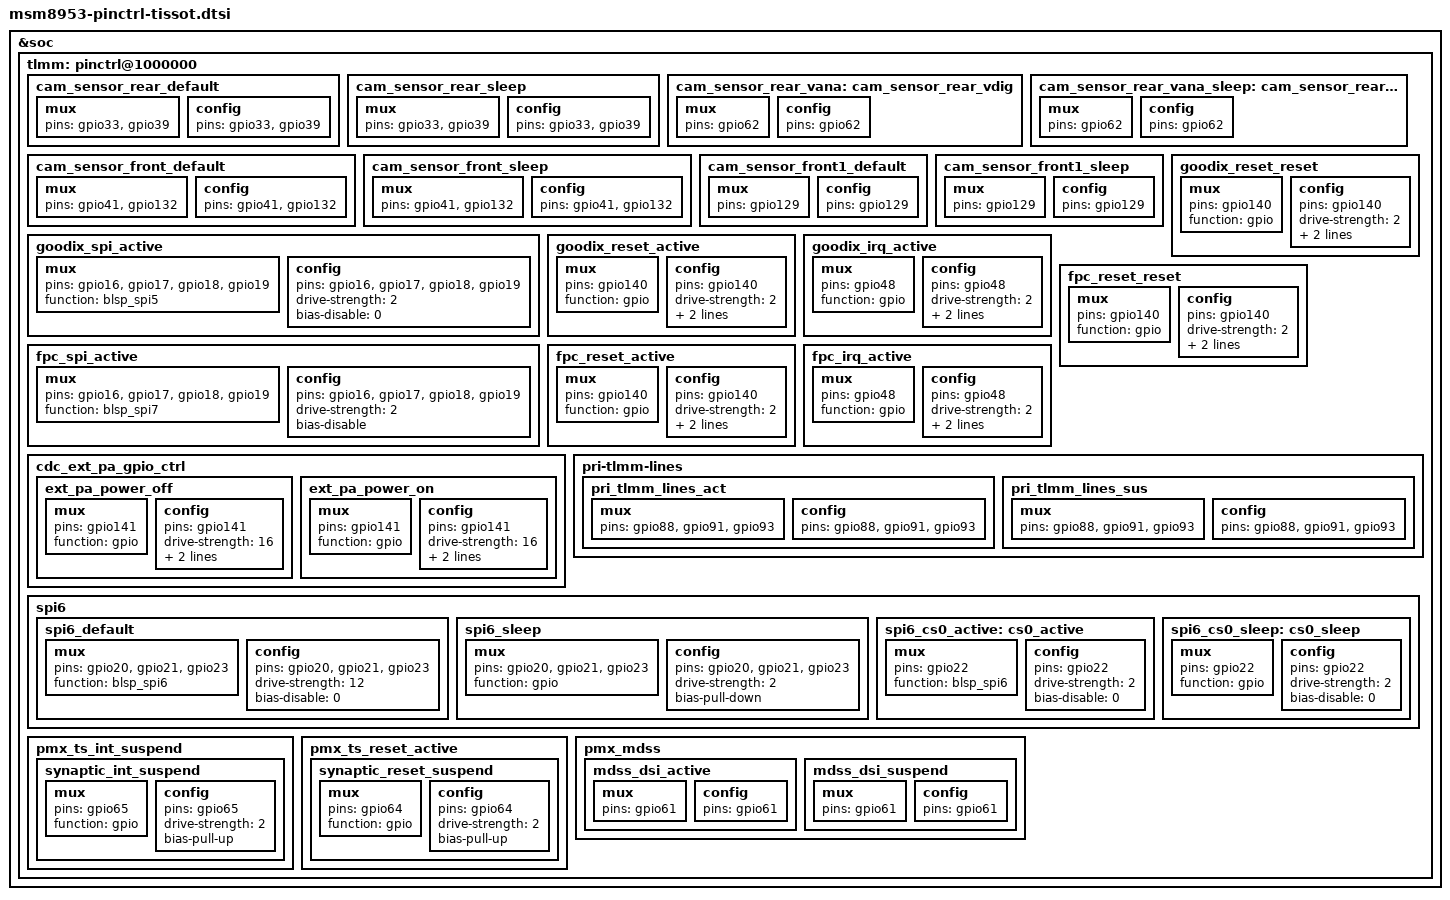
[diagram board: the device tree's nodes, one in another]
/*
 * Copyright (c) 2015-2017, The Linux Foundation. All rights reserved.
 *
 * This program is free software; you can redistribute it and/or modify
 * it under the terms of the GNU General Public License version 2 and
 * only version 2 as published by the Free Software Foundation.
 *
 * This program is distributed in the hope that it will be useful,
 * but WITHOUT ANY WARRANTY; without even the implied warranty of
 * MERCHANTABILITY or FITNESS FOR A PARTICULAR PURPOSE.  See the
 * GNU General Public License for more details.
 */

&soc {
	tlmm: pinctrl@1000000 {
		cam_sensor_rear_default: cam_sensor_rear_default {
			/* RESET, STANDBY */
			mux {
				pins = "gpio33", "gpio39";
			};

			config {
				pins = "gpio33","gpio39";
			};
		};

		cam_sensor_rear_sleep: cam_sensor_rear_sleep {
			/* RESET, STANDBY */
			mux {
				pins = "gpio33","gpio39";
			};

			config {
				pins = "gpio33","gpio39";
			};
		};

		/delete-node/ cam_sensor_ir_cut_default;
		/delete-node/ cam_sensor_ir_cut_sleep;
		/delete-node/ cam_sensor_rear_default1;
		/delete-node/ cam_sensor_rear_sleep1;

		cam_sensor_rear_vana: cam_sensor_rear_vdig {
			/* VDIG */
			mux {
				pins = "gpio62";
			};

			config {
				pins = "gpio62";
			};
		};

		cam_sensor_rear_vana_sleep: cam_sensor_rear_vdig_sleep {
			/* VDIG */
			mux {
				pins = "gpio62";
			};

			config {
				pins = "gpio62";
			};
		};

		/delete-node/ cam_sensor_rear_vdig1;
		/delete-node/ cam_sensor_rear_vdig_sleep1;

		cam_sensor_front_default: cam_sensor_front_default {
			/* RESET, STANDBY */
			mux {
				pins = "gpio41","gpio132";
			};

			config {
				pins = "gpio41","gpio132";
			};
		};

		cam_sensor_front_sleep: cam_sensor_front_sleep {
			/* RESET, STANDBY */
			mux {
				pins = "gpio41","gpio132";
			};

			config {
				pins = "gpio41","gpio132";
			};
		};

		cam_sensor_front1_default: cam_sensor_front1_default {
			/* RESET, STANDBY */
			mux {
				pins = "gpio129";
			};

			config {
				pins = "gpio129";
			};
		};

		cam_sensor_front1_sleep: cam_sensor_front1_sleep {
			/* RESET, STANDBY */
			mux {
				pins = "gpio129";
			};

			config {
				pins = "gpio129";
			};
		};

		goodix_spi_active: goodix_spi_active{
			mux {
				pins = "gpio16", "gpio17", "gpio18", "gpio19";
				function = "blsp_spi5";
			};
			config {
				pins = "gpio16", "gpio17", "gpio18", "gpio19";
				drive-strength = <2>;
				bias-disable = <0>;
			};
		};
		goodix_reset_reset: goodix_reset_reset{
			mux {
				pins = "gpio140";
				function = "gpio";
			};
			config {
				pins = "gpio140";
				drive-strength = <2>;
				bias-disable = <0>;
				output-low;
			};
		};
		goodix_reset_active: goodix_reset_active{
			mux {
				pins = "gpio140";
				function = "gpio";
			};
			config {
				pins = "gpio140";
				drive-strength = <2>;
				bias-disable = <0>;
				output-high;
			};
		};
		goodix_irq_active: goodix_irq_active {
			mux {
				pins = "gpio48";
				function = "gpio";
			};
			config {
				pins = "gpio48";
				drive-strength = <2>;
				bias-disable = <0>;
				input-enable;
			};
		};

		fpc_spi_active: fpc_spi_active {
			mux {
				pins = "gpio16", "gpio17", "gpio18", "gpio19";
				function = "blsp_spi7";
			};

			config {
				pins = "gpio16", "gpio17", "gpio18", "gpio19";
				drive-strength = <2>;
				bias-disable;
			};
		};
		fpc_reset_reset: fpc_reset_reset {
			mux {
				pins = "gpio140";
				function = "gpio";
			};
			config {
				pins = "gpio140";
				drive-strength = <2>;
				bias-disable;
				output-low;
			};
		};
		fpc_reset_active: fpc_reset_active {
			mux {
				pins = "gpio140";
				function = "gpio";
			};
			config {
				pins = "gpio140";
				drive-strength = <2>;
				bias-disable;
				output-high;
			};
		};
		fpc_irq_active: fpc_irq_active {
			mux {
				pins = "gpio48";
				function = "gpio";
			};
			config {
				pins = "gpio48";
				drive-strength = <2>;
				bias-disable;
				input-enable;
			};
		};

		cdc_ext_pa_gpio_ctrl {
			ext_pa_power_off:ext_pa_power_off{
				mux {
					pins = "gpio141";
					function = "gpio";
				};
				config {
					pins = "gpio141";
					drive-strength = <16>;
					bias-disable;
					output-low;
				};
			};
			ext_pa_power_on:ext_pa_power_on{
				mux {
					pins = "gpio141";
					function = "gpio";
				};
				config {
					pins = "gpio141";
					drive-strength = <16>;
					bias-pull-down;
					output-high;
				};
			};
		};

		pri-tlmm-lines {
			pri_tlmm_lines_act: pri_tlmm_lines_act {
				mux {
					pins = "gpio88", "gpio91", "gpio93";
				};

				config {
					pins = "gpio88", "gpio91", "gpio93";
				};
			};

			pri_tlmm_lines_sus: pri_tlmm_lines_sus {
				mux {
					pins = "gpio88", "gpio91", "gpio93";
				};

				config {
					pins = "gpio88", "gpio91", "gpio93";
				};
			};
		};

		spi6 {
			spi6_default: spi6_default {
				/* active state */
				mux {
					/* MOSI, MISO, CLK */
					pins = "gpio20", "gpio21", "gpio23";
					function = "blsp_spi6";
				};

				config {
					pins = "gpio20", "gpio21", "gpio23";
					drive-strength = <12>; /* 12 MA */
					bias-disable = <0>; /* No PULL */
				};
			};

			spi6_sleep: spi6_sleep {
				/* suspended state */
				mux {
					/* MOSI, MISO, CLK */
					pins = "gpio20", "gpio21", "gpio23";
					function = "gpio";
				};

				config {
					pins = "gpio20", "gpio21", "gpio23";
					drive-strength = <2>; /* 2 MA */
					bias-pull-down; /* PULL Down */
				};
			};

			spi6_cs0_active: cs0_active {
				/* CS */
				mux {
					pins = "gpio22";
					function = "blsp_spi6";
				};

				config {
					pins = "gpio22";
					drive-strength = <2>;
					bias-disable = <0>;
				};
			};

			spi6_cs0_sleep: cs0_sleep {
				/* CS */
				mux {
					pins = "gpio22";
					function = "gpio";
				};

				config {
					pins = "gpio22";
					drive-strength = <2>;
					bias-disable = <0>;
				};
			};
		};

		pmx_ts_int_suspend {
			synaptic_int_suspend: synaptic_int_suspend {
				mux {
					pins = "gpio65";
					function = "gpio";
				};

				config {
					pins = "gpio65";
					drive-strength = <2>;
					bias-pull-up;
				};
			};
		};

		pmx_ts_reset_active {
			synaptic_reset_suspend: synaptic_reset_suspend {
				mux {
					pins = "gpio64";
					function = "gpio";
				};

				config {
					pins = "gpio64";
					drive-strength = <2>;
					bias-pull-up;
				};
			};
		};

		pmx_mdss {
			mdss_dsi_active: mdss_dsi_active {
				mux {
					pins = "gpio61";
				};
				config {
					pins = "gpio61";
				};
			};
			mdss_dsi_suspend: mdss_dsi_suspend {
				mux {
					pins = "gpio61";
				};
				config {
					pins = "gpio61";
				};
			};
		};
	};
};
